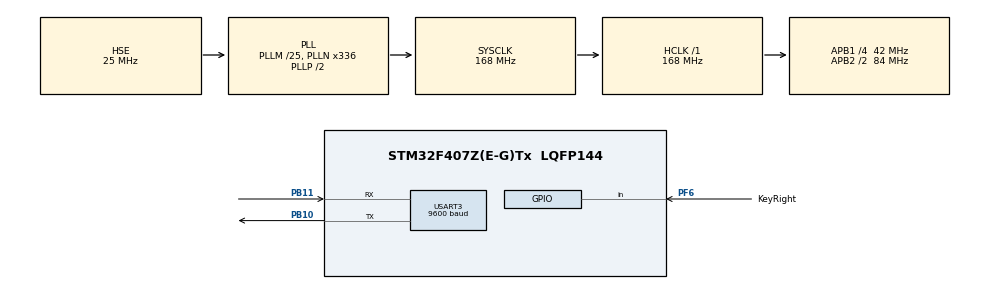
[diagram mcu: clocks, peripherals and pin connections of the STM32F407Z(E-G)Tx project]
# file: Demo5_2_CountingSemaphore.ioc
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FREERTOS.CountingSemaphores01=Sem_Tables,5,Dynamic,NULL,0
FREERTOS.Tasks01=Task_CheckIn,24,128,AppTask_CheckIn,Default,NULL,Dynamic,NULL,NULL
FREERTOS.configUSE_NEWLIB_REENTRANT=1
Mcu.Family=STM32F4
Mcu.Name=STM32F407Z(E-G)Tx
Mcu.Package=LQFP144
NVIC.PriorityGroup=NVIC_PRIORITYGROUP_4
NVIC.RTC_WKUP_IRQn=true\:5\:0\:false\:false\:true\:true\:true\:true\:true
NVIC.TIM6_DAC_IRQn=true\:0\:0\:true\:false\:true\:false\:false\:true\:true
NVIC.TimeBase=TIM6_DAC_IRQn
NVIC.TimeBaseIP=TIM6
PA13.Mode=Serial_Wire
PA13.Signal=SYS_JTMS-SWDIO
PA14.Mode=Serial_Wire
PA14.Signal=SYS_JTCK-SWCLK
PB10.Mode=Asynchronous
PB10.Signal=USART3_TX
PB11.Mode=Asynchronous
PB11.Signal=USART3_RX
PC14-OSC32_IN.Mode=LSE-External-Oscillator
PC14-OSC32_IN.Signal=RCC_OSC32_IN
PC15-OSC32_OUT.Mode=LSE-External-Oscillator
PC15-OSC32_OUT.Signal=RCC_OSC32_OUT
PF6.GPIO_Label=KeyRight
PF6.GPIO_PuPd=GPIO_PULLUP
PF6.Signal=GPIO_Input
PH0-OSC_IN.Mode=HSE-External-Oscillator
PH0-OSC_IN.Signal=RCC_OSC_IN
PH1-OSC_OUT.Mode=HSE-External-Oscillator
PH1-OSC_OUT.Signal=RCC_OSC_OUT
ProjectManager.HeapSize=0x200
ProjectManager.StackSize=0x400
ProjectManager.TargetToolchain=STM32CubeIDE
RCC.48MHZClocksFreq_Value=84000000
RCC.AHBFreq_Value=168000000
RCC.APB1CLKDivider=RCC_HCLK_DIV4
RCC.APB1Freq_Value=42000000
RCC.APB1TimFreq_Value=84000000
RCC.APB2CLKDivider=RCC_HCLK_DIV2
RCC.APB2Freq_Value=84000000
RCC.APB2TimFreq_Value=168000000
RCC.CortexFreq_Value=168000000
RCC.HCLKFreq_Value=168000000
RCC.HSE_VALUE=25000000
RCC.HSI_VALUE=16000000
RCC.PLLM=25
RCC.PLLN=336
RCC.PLLSourceVirtual=RCC_PLLSOURCE_HSE
RCC.RCC_RTC_Clock_Source=RCC_RTCCLKSOURCE_LSE
RCC.SYSCLKFreq_VALUE=168000000
RCC.SYSCLKSource=RCC_SYSCLKSOURCE_PLLCLK
RCC.VCOOutputFreq_Value=336000000
RTC.Date=25
RTC.Format=RTC_FORMAT_BIN
RTC.Hours=9
RTC.Minutes=6
RTC.Month=RTC_MONTH_APRIL
RTC.Seconds=10
RTC.WakeUpClock=RTC_WAKEUPCLOCK_CK_SPRE_16BITS
RTC.WakeUpCounter=2
RTC.WeekDay=RTC_WEEKDAY_FRIDAY
RTC.Year=25
USART3.BaudRate=9600
USART3.VirtualMode=VM_ASYNC
VP_FREERTOS_VS_CMSIS_V2.Mode=CMSIS_V2
VP_RTC_VS_RTC_Activate.Mode=RTC_Enabled
VP_RTC_VS_RTC_Calendar.Mode=RTC_Calendar
VP_RTC_VS_RTC_WakeUp_intern.Mode=WakeUp
VP_SYS_VS_tim6.Mode=TIM6
board=custom

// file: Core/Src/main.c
/* USER CODE BEGIN Header */
/**
  ******************************************************************************
  * @file           : main.c
  * @brief          : Main program body
  ******************************************************************************
  * @attention
  *
  * Copyright (c) 2025 STMicroelectronics.
  * All rights reserved.
  *
  * This software is licensed under terms that can be found in the LICENSE file
  * in the root directory of this software component.
  * If no LICENSE file comes with this software, it is provided AS-IS.
  *
  ******************************************************************************
  */
/* USER CODE END Header */
#include "main.h"
#include "cmsis_os.h"
#include "rtc.h"
#include "usart.h"
#include "gpio.h"

/* USER CODE BEGIN Includes */
#include <stdio.h>
/* USER CODE END Includes */

void SystemClock_Config(void);
void MX_FREERTOS_Init(void);

int main(void)
{

  /* MCU Configuration--------------------------------------------------------*/

  /* Reset of all peripherals, Initializes the Flash interface and the Systick. */
  HAL_Init();

  /* Configure the system clock */
  SystemClock_Config();

  /* Initialize all configured peripherals */
  MX_GPIO_Init();
  MX_RTC_Init();
  MX_USART3_UART_Init();
  /* USER CODE BEGIN 2 */
  //startup menu
   uint8_t startstr[] = "Demo5_2: Counting Semaphore.\r\n";
   HAL_UART_Transmit(&huart3,startstr,sizeof(startstr),0xFFFF);
   uint8_t startstr1[] = "Press S5=KeyRight to check in.\r\n";
   HAL_UART_Transmit(&huart3,startstr1,sizeof(startstr1),0xFFFF);
   uint8_t startstr2[] = "Auto Check out every 3sec.\r\n\r\n";
   HAL_UART_Transmit(&huart3,startstr2,sizeof(startstr2),0xFFFF);

  /* USER CODE END 2 */

  /* Init scheduler */
  osKernelInitialize();

  /* Call init function for freertos objects (in cmsis_os2.c) */
  MX_FREERTOS_Init();

  /* Start scheduler */
  osKernelStart();

  /* We should never get here as control is now taken by the scheduler */

  /* Infinite loop */
  while (1)
  {

  }
}

void SystemClock_Config(void)
{
  RCC_OscInitTypeDef RCC_OscInitStruct = {0};
  RCC_ClkInitTypeDef RCC_ClkInitStruct = {0};

  /** Configure the main internal regulator output voltage
  */
  __HAL_RCC_PWR_CLK_ENABLE();
  __HAL_PWR_VOLTAGESCALING_CONFIG(PWR_REGULATOR_VOLTAGE_SCALE1);

  /** Initializes the RCC Oscillators according to the specified parameters
  * in the RCC_OscInitTypeDef structure.
  */
  RCC_OscInitStruct.OscillatorType = RCC_OSCILLATORTYPE_HSE|RCC_OSCILLATORTYPE_LSE;
  RCC_OscInitStruct.HSEState = RCC_HSE_ON;
  RCC_OscInitStruct.LSEState = RCC_LSE_ON;
  RCC_OscInitStruct.PLL.PLLState = RCC_PLL_ON;
  RCC_OscInitStruct.PLL.PLLSource = RCC_PLLSOURCE_HSE;
  RCC_OscInitStruct.PLL.PLLM = 25;
  RCC_OscInitStruct.PLL.PLLN = 336;
  RCC_OscInitStruct.PLL.PLLP = RCC_PLLP_DIV2;
  RCC_OscInitStruct.PLL.PLLQ = 4;
  if (HAL_RCC_OscConfig(&RCC_OscInitStruct) != HAL_OK)
  {
    Error_Handler();
  }

  /** Initializes the CPU, AHB and APB buses clocks
  */
  RCC_ClkInitStruct.ClockType = RCC_CLOCKTYPE_HCLK|RCC_CLOCKTYPE_SYSCLK
                              |RCC_CLOCKTYPE_PCLK1|RCC_CLOCKTYPE_PCLK2;
  RCC_ClkInitStruct.SYSCLKSource = RCC_SYSCLKSOURCE_PLLCLK;
  RCC_ClkInitStruct.AHBCLKDivider = RCC_SYSCLK_DIV1;
  RCC_ClkInitStruct.APB1CLKDivider = RCC_HCLK_DIV4;
  RCC_ClkInitStruct.APB2CLKDivider = RCC_HCLK_DIV2;

  if (HAL_RCC_ClockConfig(&RCC_ClkInitStruct, FLASH_LATENCY_5) != HAL_OK)
  {
    Error_Handler();
  }
}

void HAL_TIM_PeriodElapsedCallback(TIM_HandleTypeDef *htim)
{
  if (htim->Instance == TIM6)
  {
    HAL_IncTick();
  }
}

void Error_Handler(void)
{
  __disable_irq();
  while (1)
  {
  }
}

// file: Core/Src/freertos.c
/* USER CODE BEGIN Header */
/**
  ******************************************************************************
  * File Name          : freertos.c
  * Description        : Code for freertos applications
  ******************************************************************************
  * @attention
  *
  * Copyright (c) 2025 STMicroelectronics.
  * All rights reserved.
  *
  * This software is licensed under terms that can be found in the LICENSE file
  * in the root directory of this software component.
  * If no LICENSE file comes with this software, it is provided AS-IS.
  *
  ******************************************************************************
  */
/* USER CODE END Header */

#include "FreeRTOS.h"
#include "task.h"
#include "main.h"
#include "cmsis_os.h"

/* USER CODE BEGIN Includes */
#include "semphr.h"
#include <stdio.h>
#include "usart.h"
/* USER CODE END Includes */

/* Definitions for Task_CheckIn */
osThreadId_t Task_CheckInHandle;
const osThreadAttr_t Task_CheckIn_attributes = {
  .name = "Task_CheckIn",
  .stack_size = 128 * 4,
  .priority = (osPriority_t) osPriorityNormal,
};
/* Definitions for Sem_Tables */
osSemaphoreId_t Sem_TablesHandle;
const osSemaphoreAttr_t Sem_Tables_attributes = {
  .name = "Sem_Tables"
};

void AppTask_CheckIn(void *argument);

void MX_FREERTOS_Init(void); /* (MISRA C 2004 rule 8.1) */

void MX_FREERTOS_Init(void) {

  /* Create the semaphores(s) */
  /* creation of Sem_Tables */
  Sem_TablesHandle = osSemaphoreNew(5, 0, &Sem_Tables_attributes);

  /* Create the thread(s) */
  /* creation of Task_CheckIn */
  Task_CheckInHandle = osThreadNew(AppTask_CheckIn, NULL, &Task_CheckIn_attributes);

}

void AppTask_CheckIn(void *argument)
{
  /* USER CODE BEGIN AppTask_CheckIn */
	UBaseType_t totalTables=uxSemaphoreGetCount(Sem_TablesHandle);						///<Get Semaphore Count
	printf("Total tables=  %ld.\r\n",totalTables);

	/* Infinite loop */
	for(;;)
	{
		GPIO_PinState keyState=HAL_GPIO_ReadPin(KeyRight_GPIO_Port, KeyRight_Pin); 	///<PA6=KeyRight
		if (keyState==GPIO_PIN_RESET)  																			///<KeyRight Active low
		{
			BaseType_t result=xSemaphoreTake(Sem_TablesHandle, pdMS_TO_TICKS(100));
			if (result==pdTRUE)
				printf("Check in OK. \r\n");
			else
				printf("Check in fail. \r\n");
			vTaskDelay(pdMS_TO_TICKS(300)); ///<Delay, remove jitter effects, and allow task scheduling to be executed
		}
		UBaseType_t availableTables=uxSemaphoreGetCount(Sem_TablesHandle);
		printf("Available tables=  %ld.\r\n",availableTables);
		vTaskDelay(pdMS_TO_TICKS(10));
	}
  /* USER CODE END AppTask_CheckIn */
}

/* USER CODE BEGIN Application */
/**	WakeUpTimerEvent ISR
 * The WakeUp is interrupted every 3s,
 * and the semaphore is released
 * and a scheduling task is applied for each interrupt.
 *
 */
void HAL_RTCEx_WakeUpTimerEventCallback(RTC_HandleTypeDef *hrtc)
{
	if (Sem_TablesHandle != NULL)
	{
		BaseType_t  highTaskWoken=pdFALSE;
		xSemaphoreGiveFromISR(Sem_TablesHandle, &highTaskWoken);
		portYIELD_FROM_ISR(highTaskWoken);
	}
}

int __io_putchar(int ch)
{
	HAL_UART_Transmit(&huart3,(uint8_t*)&ch,1,0xFFFF);
	return ch;
}
/* USER CODE END Application */
